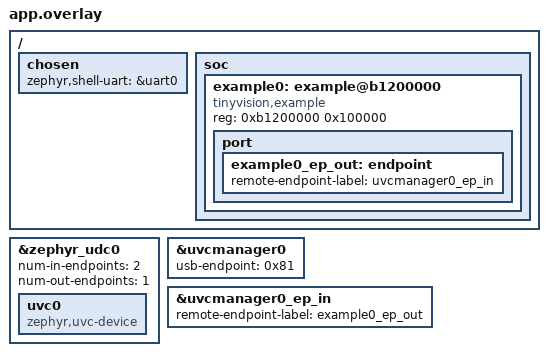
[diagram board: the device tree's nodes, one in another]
/*
 * Copyright (c) 2024-2025 tinyVision.ai Inc.
 *
 * SPDX-License-Identifier: Apache-2.0
 */

#include <riscv/tinyvision/tinyclunx33_add_opencores_i2c.dtsi>
#include <riscv/tinyvision/tinyclunx33_add_csi0.dtsi>
#include <riscv/tinyvision/tinyclunx33_add_debayer0.dtsi>
#include <riscv/tinyvision/tinyclunx33_add_uvcmanager0.dtsi>

/ {
	chosen {
		zephyr,shell-uart = &uart0;
	};

	soc {
		example0: example@b1200000 {
			compatible = "tinyvision,example";
			reg = <0xb1200000 0x100000>;

			port {
				example0_ep_out: endpoint {
					remote-endpoint-label = "uvcmanager0_ep_in";
				};
			};
		};
	};
};

&zephyr_udc0 {
	num-in-endpoints = <2>;
	num-out-endpoints = <1>;
	status = "okay";

	uvc0: uvc0 {
		compatible = "zephyr,uvc-device";
	};
};

&uvcmanager0 {
	usb-endpoint = <0x81>;
	status = "okay";
};

&uvcmanager0_ep_in {
	remote-endpoint-label = "example0_ep_out";
};
